# SPC1068 register map
File version: 20180100_70611510
CPU: CM3 r2p1, little endian, MPU, no FPU, 4 interrupt priority bits
Registers are 32-bit, read-write, reset 0x0 unless marked. A register's access mark holds for its fields unless they carry their own. Offsets are from the block's base; [hi:lo] are bit positions; {n}, {i} and the like mark numbered series; 'fields as' and 'values as' point back to an identical list.

## PWM0 — NOEN
Base 0x40007000
Same registers: PWM1 0x40007100, PWM2 0x40007200, PWM3 0x40007300, PWM4 0x40007400, PWM5 0x40007500, PWM6 0x40007600
0x00 TBPRD — Time-Base Period Register
  [15:0] VAL — Time-base counter period. TBCTL.PRDLD=0: Access to this register will actually goes to the internal shadow register (sharing the same address), and the active value will be updated from shadow register when TBCNT is zero. TBCTL.PRDLD=1: Access to this register will directly affect the active value.
0x04 TBPHS — Time-Base Phase Register
  [15:0] VAL — Time-base counter phase when synchronization event occurs. TBCTL.PHSEN=0: The synchronization event is ignored and TBCNT keeps its value. TBCTL.PHSEN=1: Time-base counter (TBCNT) will be loaded with TBPHS when synchronization event occurs.
0x08 TBCNT ro — Time-Base Counter Register
  [15:0] VAL — Current value of the time-base counter
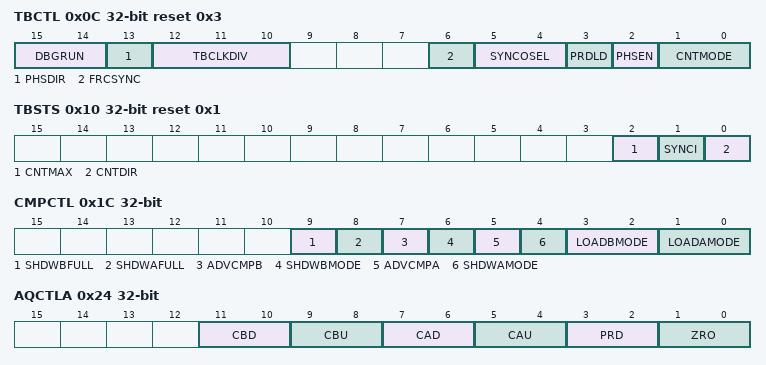
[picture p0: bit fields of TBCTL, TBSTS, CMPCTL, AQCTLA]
0x0C TBCTL reset 0x3 — Time-Base Control Register
  [15:14] DBGRUN — PWM counter behaviour when CPU is halted . Note: Debug operation and CPU fault exceptions both can cause CPU halted.
    0=STOP_AFTER_COUNTING (Stop after the next time-base counter increment or decrement); 1=STOP_AFTER_CYCLE (Stop when TBCNT completes a whole cycle (TBCNT=TBPRD for up-count mode and zero for other modes)); 2=KEEP_RUN (Counter keep running when CPU is halted)
  [13] PHSDIR — Phase direction. It is valid only when TBCNT is in up-down-count mode (CNTMODE=10)
    0=COUNT_DOWN_AFTER_SYNC (Count down after synchronization event); 1=COUNT_UP_AFTER_SYNC (Count up after synchronization event)
  [12:10] TBCLKDIV — Time-base clock dividing ratio from PWM clock input
    0=/1 (default on reset); 1=2; 2=4; 3=8; 4=16; 5=32; 6=64; 7=128
  [6] FRCSYNC — Software forced synchronization. This event is ORed with SYNCI input and is valid only when SYNCOSEL=00
    0=NO_EFFECT (Write a 0 has no effect and reads always return a 0); 1=ENABLE (Write a 1 forces a one-time synchronization pulse)
  [5:4] SYNCOSEL — Synchronization output select
    0=PWMxSYNC (SYNCI); 1=TBCNT_EQU_ZERO (TBCNT=Zero); 2=TBCNT_EQU_CMPB (TBCNT=TBPRD); 3=DISABLE (Disable SYNCO)
  [3] PRDLD — Time-base counter period register (TBPRD) load mode
    0=TBPRD_FROM_SHADOW (TBPRD is loaded from its shadow register when time-base counter (TBCNT) is zero); 1=TBPRD_IMMEDIATE (TBPRD is directly accessed without a shadow register)
  [2] PHSEN — Phase register enable
    0=DISABLE (Do not load time-base counter (TBCNT) from time-base phase register (TBPHS)); 1=ENABLE (Load TBCNT from TBPHS when synchronization event occurs (SYNCI input, software synchronization or digital compare sync event))
  [1:0] CNTMODE — Counter mode
    0=COUNT_UP_AND_RUN (Up-count); 1=COUNT_DOWN_AND_RUN (Down-count); 2=COUNT_UP_DOWN_AND_RUN (Up-down-count); 3=COUNT_STOP (Stop and freeze (default on reset))
0x10 TBSTS reset 0x1 — Time-Base Status Register
  [2] CNTMAX — Time-base counter reaching max latched status
    0=NOT_REACHED (Reading a 0 indicates TBCNT never reaches 0xFFFF. Writing a 0 has no effect.); 1=REACHED (Reading a 1 indicates TBCNT reached 0xFFFF. Writing a 1 will clear the latched status.)
  [1] SYNCI — Input synchronization latched status
    0=NO_EVENT (Reading a 0 indicates no input synchronization event has occurred. Writing a 0 has no effect.); 1=EVENT_OCCUR (Reading a 1 indicates an input synchronization event has occurred. Writing a 1 will clear the latched status.)
  [0] CNTDIR ro — Time-base counter direction status
    0=COUNTING_DOWN (Time-base counter is currently counting down); 1=COUNTING_UP (Time-base counter is currently counting up)
0x14 CMPA — Counter-Compare A Threshold Register
  [15:0] VAL — Comparator A threshold. A TBCNT=CMPA event will be generated while TBCNT is equal to the threshold value. CMPCTL.SHDWAMODE=0: Access to this register will actually go to the internal shadow register. The CMPCTL.LOADAMODE determines when the active value will be loaded from the shadow register. CMPCTL.SHDWAMODE=1: Access to this register will directly affect the active value.
0x18 CMPB — Counter-Compare B Threshold Register
  [15:0] VAL — Comparator B threshold. A TBCNT=CMPB event will be generated while TBCNT is equal to the threshold value. CMPCTL.SHDWBMODE=0: Access to this register will actually go to the internal shadow register. The CMPCTL.LOADBMODE determines when the active value will be loaded from the shadow register. CMPCTL.SHDWBMODE=1: Access to this register will directly affect the active value.
0x1C CMPCTL — Counter-Compare Control Register
  [9] SHDWBFULL ro — CMPB shadow register full status flag. A write to the shadow register will overwrite current value. A load from the shadow register to the active register will clear this bit.
    0=NOT_OCCUR (CMPB shadow FIFO not full yet); 1=OCCUR (CMPB shadow FIFO is full)
  [8] SHDWAFULL ro — CMPA shadow register full status flag. A write to the shadow register will overwrite current value. A load from the shadow register to the active register will clear this bit.
    0=NOT_OCCUR (CMPA shadow FIFO not full yet); 1=OCCUR (CMPA shadow FIFO is full)
  [7] ADVCMPB — Advanced mode for CMPB
    0=NORMAL_MODE (Normal mode: No TBCNT=CMPB event will be generated when CMPB=0 or CMPB=TBPRD); 1=ADVANCED_MODE (Advanced mode: CMPB can be 0 or TBPRD)
  [6] SHDWBMODE — CMPB register mode
    0=SHADOW_MODE; 1=IMMEDIATE_MODE
  [5] ADVCMPA — Advanced mode for CMPA
    0=NORMAL_MODE (Normal mode: No TBCNT=CMPA event will be generated when CMPA=0 or CMPA=TBPRD); 1=ADVANCED_MODE (Advanced mode: CMPA can be 0 or TBPRD)
  [4] SHDWAMODE — CMPA register mode
    0=SHADOW_MODE; 1=IMMEDIATE_MODE
  [3:2] LOADBMODE — Mode to load CMPB active value from shadow register. It has no effect when CMPCTL.SHDWBMODE=1
    0=LOAD_ON_ZERO (Load on TBCNT=Zero); 1=LOAD_ON_PERIOD (Load on TBCNT=TBPRD); 2=LOAD_ON_ZERO_PERIOD (Load on either TBCNT=Zero or TBCNT=TBPRD); 3=FREEZE (Freeze CMPA active value (No loads possible))
  [1:0] LOADAMODE — Mode to load CMPA active value from shadow register. It has no effect when CMPCTL.SHDWAMODE=1
    values as LOADBMODE
0x24 AQCTLA — Action-Qualifier Output A Control Register
  [all] fields
    0=DO_NOTHING (Do nothing (action disabled)); 1=SET_LOW (Clear (force PWM output A to low)); 2=SET_HIGH (Set (force PWM output A to high)); 3=TOGGLE (Toggle (invert current PWM output A status))
  [11:10] CBD — Action on output A when TBCNT=CMPB and TBCNT is counting down
  [9:8] CBU — Action on output A when TBCNT=CMPB and TBCNT is counting up
  [7:6] CAD — Action on output A when TBCNT=CMPA and TBCNT is counting down
  [5:4] CAU — Action on output A when TBCNT=CMPA and TBCNT is counting up
  [3:2] PRD — Action on output A when TBCNT=TBPRD
  [1:0] ZRO — Action on output A when TBCNT=Zero
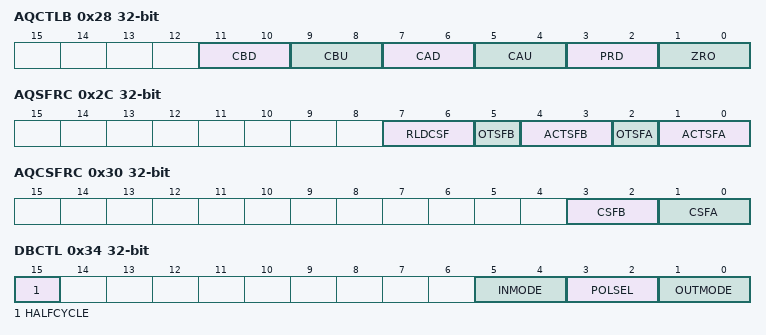
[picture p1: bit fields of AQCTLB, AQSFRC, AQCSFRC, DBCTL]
0x28 AQCTLB — Action-Qualifier B Control Register
  [all] fields
    0=DO_NOTHING (Do nothing (action disabled)); 1=SET_LOW (Clear (force PWM output B to low)); 2=SET_HIGH (Set (force PWM output B to high)); 3=TOGGLE (Toggle (invert current PWM output B status))
  [11:10] CBD — Action on output B when TBCNT=CMPA and TBCNT is counting down
  [9:8] CBU — Action on output B when TBCNT=CMPB and TBCNT is counting up
  [7:6] CAD — Action on output B when TBCNT=CMPA and TBCNT is counting down
  [5:4] CAU — Action on output B when TBCNT=CMPA and TBCNT is counting up
  [3:2] PRD — Action on output B when TBCNT=TBPRD
  [1:0] ZRO — Action on output B when TBCNT=Zero
0x2C AQSFRC — Action-Qualifier Software Force Register
  [7:6] RLDCSF — Options to load continuous software force register (AQCSFRC) active value from shadow register
    0=LOAD_ON_ZERO (Load on TBCNT=Zero); 1=LOAD_ON_PERIOD (Load on TBCNT=TBPRD); 2=LOAD_ON_ZERO_PERIOD (Load on TBCNT=Zero or TBCNT=TBPRD); 3=LOAD_IMMEDIATE (Load immediately (No shadowing))
  [5] OTSFB wo — One-time software forced event on output B. This bit is auto cleared once a write to it is complete
    0=NO_EFFECT (Write a 0 has no effect. Always reads back a 0); 1=FORCE_ONE_TIME (Initiate a single software forced event)
  [4:3] ACTSFB — Action when one-time software force B is invoked
    0=DO_NOTHING (Do nothing (action disabled)); 1=SET_LOW (Clear (force PWM output B to low); 2=SET_HIGH (Set (force PWM output B to high); 3=TOGGLE (Toggle (invert current PWM output B status))
  [2] OTSFA wo — One-time software forced event on output A. This bit is auto cleared once a write to it is complete
    values as OTSFB
  [1:0] ACTSFA — Action when one-time software force A is invoked
    0=DO_NOTHING (Do nothing (action disabled)); 1=SET_LOW (Clear (force PWM output A to low); 2=SET_HIGH (Set (force PWM output A to high); 3=TOGGLE (Toggle (invert current PWM output A status))
0x30 AQCSFRC — Action-Qualifier Continuous Software Force Register
  [3:2] CSFB — Continuous software force on output B. The register can be in immediate mode or shadow mode as determined by AQSFRC.RLDCSF
    0=NO_EFFECT (Forcing disabled); 1=FORCE_CONTINUOUS_LOW (Force a continuous low on output B); 2=FORCE_CONTINUOUS_HIGH (Force a continuous high on output B); 3=DISABLE (Forcing disabled)
  [1:0] CSFA — Continuous software force on output A. The register can be in immediate mode or shadow mode as determined by AQSFRC.RLDCSF
    0=NO_EFFECT (Forcing disabled); 1=FORCE_CONTINUOUS_LOW (Force a continuous low on output A); 2=FORCE_CONTINUOUS_HIGH (Force a continuous high on output A); 3=DISABLE (Forcing disabled)
0x34 DBCTL — Dead-Band Generator Control Register
  [15] HALFCYCLE — Half cycle clocking enable
    0=DISABLE (Full cycle clocking enabled. The dead-band counter is clocked at TBCLK); 1=ENABLE (Half cycle clocking enabled. The dead-band counter is clocked at 2x TBCLK)
  [5:4] INMODE — Dead-band input mode
    0=Input A is the source for both rising-edge and falling-edge delay; 1=Input B is the source for rising-edge delay. Input A is the source for falling-edge delay; 2=Input A is the source for rising-edge delay. Input B is the source for falling-edge delay; 3=Input B is the source for both rising-edge and falling-edge delay
  [3:2] POLSEL — Polarity select
    0=MODE_AHH (Neither output A or output B is inverted (default)); 1=MODE_ALH (Output A is inverted); 2=MODE_AHL (Output B is inverted); 3=MODE_ALL (Both output A and output B are inverted)
  [1:0] OUTMODE — Dead-band output mode
    0=Dead-band is bypassed for both outputs. Input A and B from the action-qualifier are passed directly to the PWM-chopper submodule. POLSEL and IN_MODE are not used in this mode.; 1=Disable rising-edge delay. Input A from the action-qualifier is directly passed through to the input A of the PWM-chopper submodule. The falling-edge delay is applied at output B. The input signal for the delay is determined by DBCTL.IN_MODE.; 2=The rising-edge delay is applied at output A. The input signal for the delay is determined by DBCTL.IN_MODE. Disable falling-edge delay. Input B from the action-qualifier is directly passed through to the input B of the PWM-chopper submodule.; 3=Dead-band is fully enabled for both rising-edge delay on output A and falling-edge delay on output B. The input signal for the delay is determined by DBCTL.IN_MODE.
0x38 DBRED — Dead-Band Generator Rising Edge Delay Register
  [9:0] VAL — Rising-edge delay
0x3C DBFED — Dead-Band Generator Falling Edge Delay Register
  [9:0] VAL — Falling-edge delay
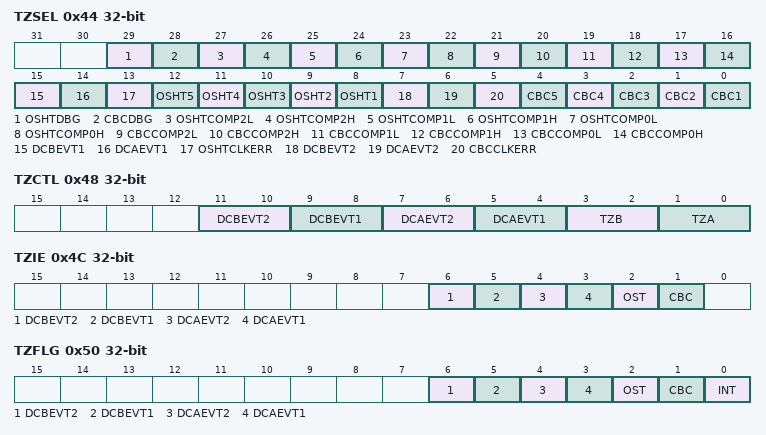
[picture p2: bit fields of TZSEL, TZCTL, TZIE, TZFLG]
0x44 TZSEL — Trip-Zone Select Register
  [29] OSHTDBG — EMUSTOP as a one-shot trip source
    0=DEBUG_DISABLE (Disable); 1=DEBUG_ENABLE (Enable)
  [28] CBCDBG — EMUSTOP as a cycle-by-cycle trip source
    0=DEBUG_DISABLE (Disable); 1=DEBUG_ENABLE (Enable)
  [27] OSHTCOMP2L — COMP2L as a one-shot trip
    0=DISABLE; 1=ENABLE
  [26] OSHTCOMP2H — COMP2H as a one-shot trip source
    0=DISABLE; 1=ENABLE
  [25] OSHTCOMP1L — COMP1L as a one-shot trip source
    0=DISABLE; 1=ENABLE
  [24] OSHTCOMP1H — COMP1H as a one-shot trip source
    0=DISABLE; 1=ENABLE
  [23] OSHTCOMP0L — COMP0L as a one-shot trip source
    0=DISABLE; 1=ENABLE
  [22] OSHTCOMP0H — COMP0H as a one-shot trip source
    0=DISABLE; 1=ENABLE
  [21] CBCCOMP2L — COMP2L as a cycle-by-cycle trip source
    0=DISABLE; 1=ENABLE
  [20] CBCCOMP2H — COMP2H as a cycle-by-cycle trip source
    0=DISABLE; 1=ENABLE
  [19] CBCCOMP1L — COMP1L as a cycle-by-cycle trip source
    0=DISABLE; 1=ENABLE
  [18] CBCCOMP1H — COMP1H as a cycle-by-cycle trip source
    0=DISABLE; 1=ENABLE
  [17] CBCCOMP0L — COMP0L as a cycle-by-cycle trip source
    0=DISABLE; 1=ENABLE
  [16] CBCCOMP0H — COMP0H as a cycle-by-cycle trip source
    0=DISABLE; 1=ENABLE
  [15] DCBEVT1 — Digital compare B event 1 as a one-shot trip source
    0=ONESHOT_DISABLE (Disable); 1=ONESHOT_ENABLE (Enable)
  [14] DCAEVT1 — Digital compare A event 1 as a one-shot trip source
    0=ONESHOT_DISABLE (Disable); 1=ONESHOT_ENABLE (Enable)
  [13] OSHTCLKERR — Clock error as a one-shot trip source
    0=DISABLE; 1=ENABLE
  [n+7] OSHT{n} (n=1..5) — TZ{n} as a one-shot trip source
    0=DISABLE; 1=ENABLE
  [7] DCBEVT2 — Digital compare output B event 2 as a cycle-by-cycle trip source
    0=CBC_DISABLE (Disable); 1=CBC_ENABLE (Enable)
  [6] DCAEVT2 — Digital compare output A event 2 as a cycle-by-cycle trip source
    0=CBC_DISABLE (Disable); 1=CBC_ENABLE (Enable)
  [5] CBCCLKERR — CLKDET error as a cycle-by-cycle trip source
    0=DISABLE; 1=ENABLE
  [n-1] CBC{n} (n=1..5) — TZ{n} as a cycle-by-cycle trip source
    0=DISABLE; 1=ENABLE
0x48 TZCTL — Trip-Zone Control Register
  [11:10] DCBEVT2 — Action on output B when a digital compare B event 2 occurs
    0=TRI_STATE (Set output B to high-impedance); 1=SET_HIGH (Force output B to high state); 2=SET_LOW (Force output B to low state); 3=DO_NOTHING (Do nothing for output B)
  [9:8] DCBEVT1 — Action on output B when a digital compare B event 1 occurs
    values as DCBEVT2
  [7:6] DCAEVT2 — Action on output A when a digital compare A event 2 occurs
    0=TRI_STATE (Set output A to high-impedance); 1=SET_HIGH (Force output A to high state); 2=SET_LOW (Force output A to low state); 3=DO_NOTHING (Do nothing for output A)
  [5:4] DCAEVT1 — Action on output A when a digital compare A event 1 occurs
    values as DCAEVT2
  [3:2] TZB — Action on output B when a trip event occurs
    values as DCBEVT2
  [1:0] TZA — Action on output A when a trip event occurs
    values as DCAEVT2
0x4C TZIE — Trip-Zone Enable Interrupt Register
  [all] fields
    0=DISABLE; 1=ENABLE
  [6] DCBEVT2 — Digital compare B event 2 interrupt
  [5] DCBEVT1 — Digital compare B event 1 interrupt
  [4] DCAEVT2 — Digital compare A event 2 interrupt
  [3] DCAEVT1 — Digital compare A event 1 interrupt
  [2] OST — One-shot trip-zone interrupt
  [1] CBC — Cycle-by-cycle trip-zone interrupt
0x50 TZFLG ro — Trip-Zone Flag Register
  [6] DCBEVT2 — Latched digital compare B event 2 status flag
    0=NOT_OCCUR (No comprator B event 2 has occurred); 1=OCCUR (Comparator B event 2 has occurred. It is cleared by writing 1 to TZCLR.DCBEVT2.)
  [5] DCBEVT1 — Latched digital compare B event 1 status flag
    0=NOT_OCCUR (No comprator B event 1 has occurred); 1=OCCUR (Comparator B event 1 has occurred. It is cleared by writing 1 to TZCLR.DCBEVT1.)
  [4] DCAEVT2 — Latched digital compare A event 2 status flag
    0=NOT_OCCUR (No comprator A event 2 has occurred); 1=OCCUR (Comparator A event 2 has occurred. It is cleared by writing 1 to TZCLR.DCAEVT2.)
  [3] DCAEVT1 — Latched digital compare A event 1 status flag
    0=NOT_OCCUR (No comprator A event 1 has occurred); 1=OCCUR (Comparator A event 1 has occurred. It is cleared by writing 1 to TZCLR.DCAEVT1.)
  [2] OST — Latched one-shot trip event status flag
    0=NOT_OCCUR (No one-shot trip event has occurred); 1=OCCUR (A one-shot trip event occurred. It is cleared by writing 1 to TZCLR.OST.)
  [1] CBC — Latched cycle-by-cycle trip event status flag
    0=NOT_OCCUR (No cycle-by-cycle trip event has occurred); 1=OCCUR (A cycle-by-cycle trip event occurred. It will remain set until it is manually cleared by wring 1 to TZCLR.CBC. If the cycle-by-cycle trip event is still present when the CBC bit is cleared, it will be immediately set agian.)
  [0] INT — Latched trip interrupt status flag
    0=NOT_OCCUR (No interrupt has been generated); 1=OCCUR (Trip-zone interrupt was generated. No further trip-zone interrupt will be generated until this flag is cleared by writing 1 to TZCLR.INT. If eigher CBC or OST flag is set, another interrupt pulse will be generated when this flag is cleared.)
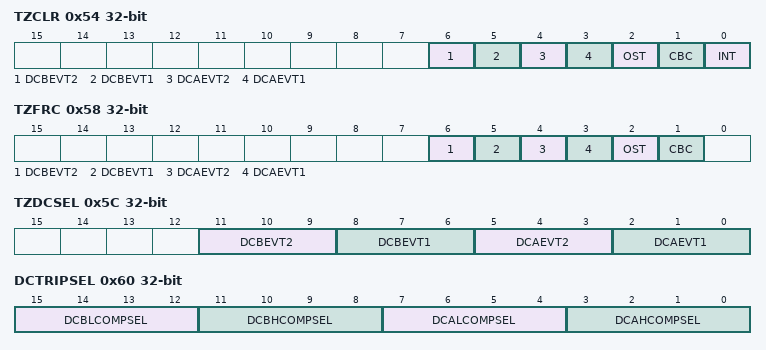
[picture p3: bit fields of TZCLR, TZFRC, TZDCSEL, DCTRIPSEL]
0x54 TZCLR — Trip-Zone Clear Register
  [6] DCBEVT2 — Clear digital compare B event 2 status flag
    0=NO_EFFECT (Write a 0 has no effect and always reads back a 0); 1=CLEAR_FLAG (Write a 1 clears TZFLG.DCBEVT2)
  [5] DCBEVT1 — Clear digital compare B event 1 status flag
    0=NO_EFFECT (Write a 0 has no effect and always reads back a 0); 1=CLEAR_FLAG (Write a 1 clears TZFLG.DCBEVT1)
  [4] DCAEVT2 — Clear digital compare A event 2 status flag
    0=NO_EFFECT (Write a 0 has no effect and always reads back a 0); 1=CLEAR_FLAG (Write a 1 clears TZFLG.DCAEVT2)
  [3] DCAEVT1 — Clear digital compare A event 1 status flag
    0=NO_EFFECT (Write a 0 has no effect and always reads back a 0); 1=CLEAR_FLAG (Write a 1 clears TZFLG.DCAEVT1)
  [2] OST — Clear one-shot trip status flag
    0=NO_EFFECT (Write a 0 has no effect and always reads back a 0); 1=CLEAR_FLAG (Write a 1 clears TZFLG.OST)
  [1] CBC — Clear cycle-by-cycle trip status flag
    0=NO_EFFECT (Write a 0 has no effect and always reads back a 0); 1=CLEAR_FLAG (Write a 1 clears TZFLG.CBC)
  [0] INT — Clear global interrupt status flag
    0=NO_EFFECT (Write a 0 has no effect and always reads back a 0); 1=CLEAR_FLAG (Write a 1 clears TZFLG.INT)
0x58 TZFRC — Trip-Zone Force Register
  [6] DCBEVT2 — Software force a digital compare B event 2
    0=NO_EFFECT (Write a 0 has no effect and always reads back a 0); 1=FORCE_EVENT (Write a 1 forces a digital compare B event 2 and sets TZFLG.DCBEVT2)
  [5] DCBEVT1 — Software force a digital compare B event 1
    0=NO_EFFECT (Write a 0 has no effect and always reads back a 0); 1=FORCE_EVENT (Write a 1 forces a digital compare B event 1 and sets TZFLG.DCBEVT1)
  [4] DCAEVT2 — Software force a digital compare A event 2
    0=NO_EFFECT (Write a 0 has no effect and always reads back a 0); 1=FORCE_EVENT (Write a 1 forces a digital compare A event 2 and sets TZFLG.DCAEVT2)
  [3] DCAEVT1 — Software force a digital compare A event 1
    0=NO_EFFECT (Write a 0 has no effect and always reads back a 0); 1=FORCE_EVENT (Write a 1 forces a digital compare A event 1 and sets TZFLG.DCAEVT1)
  [2] OST — Software force a one-shot trip event
    0=NO_EFFECT (Write a 0 has no effect and always reads back a 0); 1=FORCE_EVENT (Write a 1 forces a one-shot trip event and sets TZFLG.OST)
  [1] CBC — Software force a cycle-by-cycle trip event
    0=NO_EFFECT (Write a 0 has no effect and always reads back a 0); 1=FORCE_EVENT (Write a 1 forces a cycle-by-cycle trip event and sets TZFLG.CBC)
0x5C TZDCSEL — Trip-Zone Digital Compare Event Select Register
  [11:9] DCBEVT2 — Digital compare B event 2 option
    0=DISABLE (Event disabled); 1=DCBH_LOW_DCBL_X (DCBH=low, DCBL=don't care); 2=DCBH_HIGH_DCBL_X (DCBH=high, DCBL=don't care); 3=DCBH_X_DCBL_LOW (DCBL=low, DCBH=don't care); 4=DCBH_X_DCBL_HIGH (DCBL=high, DCBH=don't care); 5=DCBH_LOW_DCBL_HIGH (DCBL=high, DCBH=low)
  [8:6] DCBEVT1 — Digital compare B event 1 option
    values as DCBEVT2
  [5:3] DCAEVT2 — Digital compare A event 2 option
    0=DISABLE (Event disabled); 1=DCAH_LOW_DCAL_X (DCAH=low, DCAL=don't care); 2=DCAH_HIGH_DCAL_X (DCAH=high, DCAL=don't care); 3=DCAH_X_DCAL_LOW (DCAL=low, DCAH=don't care); 4=DCAH_X_DCAL_HIGH (DCAL=high, DCAH=don't care); 5=DCAH_LOW_DCAL_HIGH (DCAL=high, DCAH=low)
  [2:0] DCAEVT1 — Digital compare A event 1 option
    values as DCAEVT2
0x60 DCTRIPSEL — Digital Compare Trip Select Register
  [all] fields
    {v}=TZ{v+1} (v=0..4); 8=COMP0H; 9=COMP0L; 10=COMP1H; 11=COMP1L; 12=COMP2H; 13=COMP2L
  [15:12] DCBLCOMPSEL — Digital compare B low input select
  [11:8] DCBHCOMPSEL — Digital compare B high input select
  [7:4] DCALCOMPSEL — Digital compare A low input select
  [3:0] DCAHCOMPSEL — Digital compare A high input select
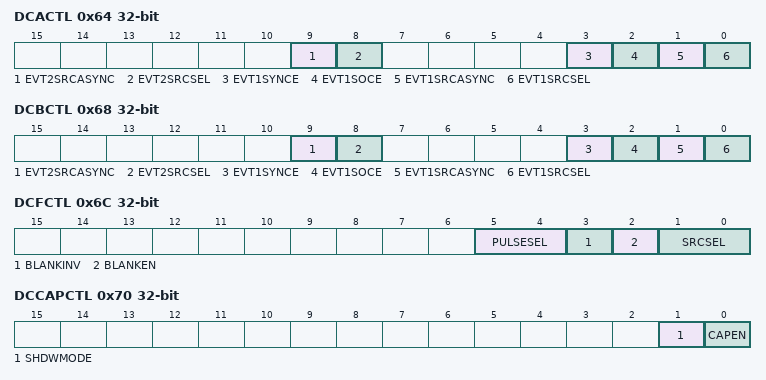
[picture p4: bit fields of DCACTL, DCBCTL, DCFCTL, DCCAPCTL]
0x64 DCACTL — Digital Compare A Control Register
  [9] EVT2SRCASYNC — DCAEVT2 source signal is asynchronous/synchronous
    0=DCAEVT2_SYNC (Synchronous); 1=DCAEVT2_ASYNC (Asynchronous)
  [8] EVT2SRCSEL — DCAEVT2 source signal select
    0=DCAEVT2 (Source signal is DCAEVT2); 1=DCEVTFILT (Source signal is DCEVTFILT)
  [3] EVT1SYNCE — DCAEVT1 SYNC generation
    0=DISABLE; 1=ENABLE
  [2] EVT1SOCE — DCAEVT1 SOC generation
    0=DISABLE; 1=ENABLE
  [1] EVT1SRCASYNC — DCAEVT1 source signal is asynchronous/synchronous (1/0)
    0=DCAEVT1_SYNC (Synchronous); 1=DCAEVT1_ASYNC (Asynchronous)
  [0] EVT1SRCSEL — DCAEVT1 source signal select
    0=DCAEVT1 (Source signal is DCAEVT1); 1=DCEVTFILT (Source signal is DCEVTFILT)
0x68 DCBCTL — Digital Compare B Control Register
  [9] EVT2SRCASYNC — DCBEVT2 source signal is asynchronous/synchronous (1/0)
    0=DCBEVT2_SYNC (None); 1=DCBEVT2_ASYNC (None)
  [8] EVT2SRCSEL — DCBEVT2 source signal select
    0=DCBEVT2 (Source signal is DCBEVT2); 1=DCEVTFILT (Source signal is DCEVTFILT)
  [3] EVT1SYNCE — DCBEVT1 SYNC generation
    0=DISABLE; 1=ENABLE
  [2] EVT1SOCE — DCBEVT1 SOC generation
    0=DISABLE; 1=ENABLE
  [1] EVT1SRCASYNC — DCBEVT1 source signal is asynchronous/synchronous
    0=DCBEVT1_SYNC (Synchronous); 1=DCBEVT1_ASYNC (Asynchronous)
  [0] EVT1SRCSEL — DCBEVT1 source signal select
    0=DCBEVT1 (Source signal is DCBEVT1); 1=DCEVTFILT (Source signal is DCEVTFILT)
0x6C DCFCTL — Digital Compare Filter Register
  [5:4] PULSESEL — Pulse select for blanking and capture alignment
    0=ALIGN_FROM_PERIOD (TBCNT=TBPRD); 1=ALIGN_FROM_ZERO (TBCNT=Zero)
  [3] BLANKINV — Blanking window inversion
    0=DISABLE; 1=ENABLE
  [2] BLANKEN — Blanking window
    0=DISABLE; 1=ENABLE
  [1:0] SRCSEL — DCEVTFILT signal source select
    0=DCAEVT1 (Source is DCAEVT1); 1=DCAEVT2 (Source is DCAEVT2); 2=DCBEVT1 (Source is DCBEVT1); 3=DCBEVT2 (Source is DCBEVT2)
0x70 DCCAPCTL — Digital Compare Capture Control Register
  [1] SHDWMODE — TBCNT capture mode select
    0=ENABLE (Shadow mode. The DCCAP active value is copied to shadow register on a TBCNT=TBPRD or TBCNT=zero event as defined by DCFCTL.PULSESEL. Reads of the DCCAP register always returns the shadow register contents.); 1=DISABLE (Direct mode. Reads of the DCCAP register always returns the active value.)
  [0] CAPEN — TBCNT counter capture
    0=ENABLE (Disable); 1=DISABLE (Enable)
0x74 DCCAP ro — Digital Compare Counter Capture Register
  [15:0] VAL — Captured TBCNT value upon a rising-edge of DCEVTFLT. In shadow mode, the captured value is copied to the shadow register on a TBCNT=TBPRD or TBCNT=zero event as defined by DCFCTL.PULSESEL. Reads of the DCCAP register always returns the shadow register contents. In direct mode, reads of the DCCAP register always returns the active value.
0x78 DCFOFFSET — Digital Compare Filter Offset Register
  [15:0] VAL — Blanking window offset. It defines the number of TBCLK cycles from the blanking window reference specified by DCFCTL.PULSESEL to the point when the blanking window is applied.
0x7C DCFOFFSETCNT ro — Digital Compare Filter Offset Counter Register
  [15:0] VAL — Blanking offset counter. It is read only and indicates the current value of the offset counter. The counter counts down to zero and then stops until it is re-loaded on the next event defined by DCFCTL.PULSESEL.
0x80 DCFWINDOW — Digital Compare Filter Window Register
  [15:0] VAL — Blanking window width in TBCLK cycles. The blanking window begins when the offset counter expires. When this occurs, the window counter is loaded and begins to count down. If the blanking window is currently active and the offset counter expires, the blanking window counter is restarted. The blanking window can cross a PWM period boundary. No blanking window is generated when it is set to zero.
0x84 DCFWINDOWCNT ro — Digital Compare Filter Window Counter Register
  [7:0] VAL — Blanking window counter. It is read only and indicates the current value of the window counter. The counter counts down to zero and then stops until it is re-loaded when the offset counter reaches zero again.
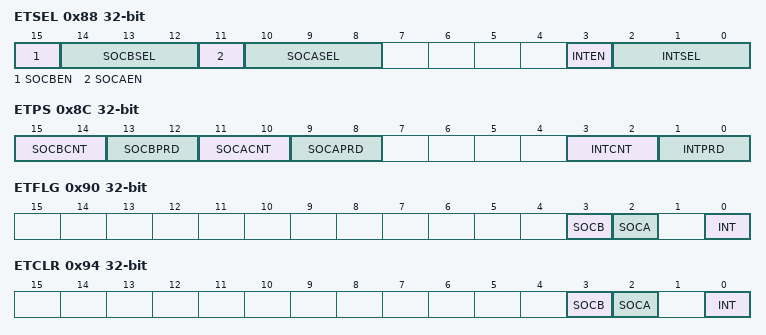
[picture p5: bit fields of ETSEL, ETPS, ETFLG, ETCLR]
0x88 ETSEL — Event-Trigger Select Register
  [15] SOCBEN — ADC start of conversion B (SOCB) pulse
    0=DISABLE; 1=ENABLE
  [14:12] SOCBSEL — PWM SOCB options
    0=DVBEVT1_SOC (Enable DCBEVT1.SOC event); 1=TBCNT_EQU_ZERO (Enable event TBCNT=0); 2=TBCNT_EQU_PERIOD (Enable event TBCNT=TBPRD); 3=TBCNT_EQU_ZERO_PERIOD (Enable event TBCNT=0 or TBCNT=TBPRD); 4=CMPA_UP_COUNTING (Enable event TBCNT=CMPA when counter is incrementing); 5=CMPA_DOWN_COUNTING (Enable event TBCNT=CMPA when counter is decrementing); 6=CMPB_UP_COUNTING (Enable event TBCNT=CMPB when counter is incrementing); 7=CMPB_DOWN_COUNTING (Enable event TBCNT=CMPB when counter is decrementing)
  [11] SOCAEN — Enable/disable ADC start of conversion A (SOCA) pulse
    0=DISABLE; 1=ENABLE
  [10:8] SOCASEL — PWM SOCA options
    0=DVAEVT1_SOC (Enable DCAEVT1.SOC event); 1=TBCNT_EQU_ZERO (Enable event TBCNT=0); 2=TBCNT_EQU_PERIOD (Enable event TBCNT=TBPRD); 3=TBCNT_EQU_ZERO_PERIOD (Enable event TBCNT=0 or TBCNT=TBPRD); 4=CMPA_UP_COUNTING (Enable event TBCNT=CMPA when counter is incrementing); 5=CMPA_DOWN_COUNTING (Enable event TBCNT=CMPA when counter is decrementing); 6=CMPB_UP_COUNTING (Enable event TBCNT=CMPB when counter is incrementing); 7=CMPB_DOWN_COUNTING (Enable event TBCNT=CMPB when counter is decrementing)
  [3] INTEN — PWM interrupt
    0=DISABLE; 1=ENABLE
  [2:0] INTSEL — PWM interrupt selection
    1=TBCNT_EQU_ZERO (Enable event TBCNT=0); 2=TBCNT_EQU_PERIOD (Enable event TBCNT=TBPRD); 3=TBCNT_EQU_ZERO_PERIOD (Enable event TBCNT=0 or TBCNT=TBPRD); 4=CMPA_UP_COUNTING (Enable event TBCNT=CMPA when counter is incrementing); 5=CMPA_DOWN_COUNTING (Enable event TBCNT=CMPA when counter is decrementing); 6=CMPB_UP_COUNTING (Enable event TBCNT=CMPB when counter is incrementing); 7=CMPB_DOWN_COUNTING (Enable event TBCNT=CMPB when counter is decrementing)
0x8C ETPS — Event-Trigger Prescale Register
  [15:14] SOCBCNT ro — PWM ADC start-of-conversion B event (SOCB) counter. It indicates how many selected ETSEL.SOCBSEL events have occurred
    0=NO_EVENT_OCCUR (No events have occurred); 1=1_EVENT_OCCUR (1 event has occurred); 2=2_EVENT_OCCUR (2 events have occurred); 3=3_EVENT_OCCUR (3 events have occurred)
  [13:12] SOCBPRD — PWM ADC start-of-conversion B event (SOCB) period select. It determines how many selected ETSEL.SOCBSEL events need to occur before an SOCB pulse is generated. To be generated, it must be enabled by setting ETSEL.SOCBEN=1. The pulse will be generated even if the status flag is set from a previous start of conversion (ETFLG.SOCB=1). Once the SOCB pulse is generated, the ETPS.SOCBCNT will automatically be cleared.
    0=GEN_SOCB_DISABLE (Disable SOCB event counter. No SOCB pulse will be generated.); 1=GEN_SOCB_ON_1ST_EVENT (Generate SOCB pulse when ETPS.SOCBCNT=01 (first event)); 2=GEN_SOCB_ON_2ND_EVENT (Generate SOCB pulse when ETPS.SOCBCNT=10 (second event)); 3=GEN_SOCB_ON_3RD_EVENT (Generate SOCB pulse when ETPS.SOCBCNT=11 (third event))
  [11:10] SOCACNT ro — PWM ADC start-of-conversion A event (SOCA) counter. It indicates how many selected ETSEL.SOCASEL events have occurred
    values as SOCBCNT
  [9:8] SOCAPRD — PWM ADC start-of-conversion A event (SOCA) period select. It determines how many selected ETSEL.SOCASEL events need to occur before an SOCA pulse is generated. To be generated, it must be enabled by setting ETSEL.SOCAEN=1. The pulse will be generated even if the status flag is set from a previous start of conversion (ETFLG.SOCA=1). Once the SOCA pulse is generated, the ETPS.SOCACNT will automatically be cleared.
    0=GEN_SOCA_DISABLE (Disable SOCA event counter. No SOCA pulse will be generated.); 1=GEN_SOCA_ON_1ST_EVENT (Generate SOCA pulse when ETPS.SOCACNT=01 (first event)); 2=GEN_SOCA_ON_2ND_EVENT (Generate SOCA pulse when ETPS.SOCACNT=10 (second event)); 3=GEN_SOCA_ON_3RD_EVENT (Generate SOCA pulse when ETPS.SOCACNT=11 (third event))
  [3:2] INTCNT ro — PWM interrupt counter. It indicates how many selected ETSEL.INTSEL events have occurred. It is automatically cleared when an interrupt pulse is generated.
    values as SOCBCNT
  [1:0] INTPRD — PWM interrupt period select. It determines how many selected ETSEL.INTSEL events need to occur before an interrupt is generated. To be generated, the interrupt must be enabled by setting ETSEL.INTEN=1. If the interrupt status flag is set from a previous interrupt (ETFLG.INT=1), no interrupt will be generated until the flag is cleared by writing a 0 to ETCLR.INT. This allows for one interrupt to be pending while another is still being serviced. Once the interrupt is generated, the ETPS.INTCNT will automatically be cleared. Write an INTPRD value that is the same as the current INTCNT value will trigger an interrupt if it is enabled and the status flag is clear. Write an INTPRD value that is less than current INTCNT value will result in an undefined state.
    0=DISABLE (Disable the interrupt event counter. No interrupt will be generated and ETFRC.INT is ignored.); 1=GEN_INT_ON_1ST_EVENT (Generate an interrupt on the first event INTCNT=01 (first event)); 2=GEN_INT_ON_2ND_EVENT (Generate interrupt on ETPS.INTCNT=10 (second event)); 3=GEN_INT_ON_3RD_EVENT (Generate interrupt on ETPS.INTCNT=11 (third event))
0x90 ETFLG ro — Event-Trigger Flag Register
  [3] SOCB — Latched PWM ADC start-of-conversion B status flag
    0=NOT_OCCUR (Indicates no event occurred); 1=OCCUR (Indicates a SOCB pulse was generated. The pulse will continue to be generated even if the flag is set.)
  [2] SOCA — Latched PWM ADC start-of-conversion A status flag
    0=NOT_OCCUR (Indicates no event occurred); 1=OCCUR (Indicates a SOCA pulse was generated. The pulse will continue to be generated even if the flag is set.)
  [0] INT — Latched PWM interrupt status flag
    0=NOT_OCCUR (Indicates no event occurred); 1=OCCUR (Indicates a PWM interrupt was generated. No further interrupts will be generated until the flag bit is cleared.)
0x94 ETCLR wo — Event-Trigger Clear Register
  [all] fields
    0=NO_EFFECT (Write a 0 has no effect and always reads back a 0); 1=CLEAR_FLAG (Write a 1 clears ETFLG.INT)
  [3] SOCB — Clear ADC start-of-conversion B status flag
  [2] SOCA — Clear ADC start-of-conversion A status flag
  [0] INT — Clear PWM interrupt status flag
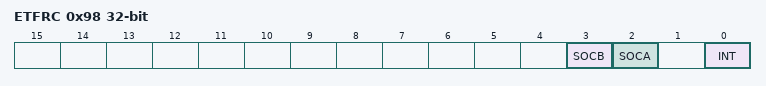
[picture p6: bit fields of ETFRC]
0x98 ETFRC wo — Event-Trigger Force Register
  [3] SOCB — Software force a start-of-conversion B pulse. This bit is ignored if ETSEL.SOCBEN=0
    0=NO_EFFECT (Write a 0 has no effect and always reads back a 0); 1=FORCE (Write a 1 generates an interrupt and sets the ETFLG.SOCB flag)
  [2] SOCA — Software force a start-of-conversion A pulse. This bit is ignored if ETSEL.SOCAEN=0
    0=NO_EFFECT (Write a 0 has no effect and always reads back a 0); 1=FORCE (Write a 1 generates an interrupt and sets the ETFLG.SOCA flag)
  [0] INT — Software force a PWM interrupt. This bit is ignored if ETSEL.INTEN=0 or ETPS.INTPRD=00
    0=NO_EFFECT (Write a 0 has no effect and always reads back a 0); 1=FORCE (Write a 1 generates an interrupt and sets the ETFLG.INT flag)
